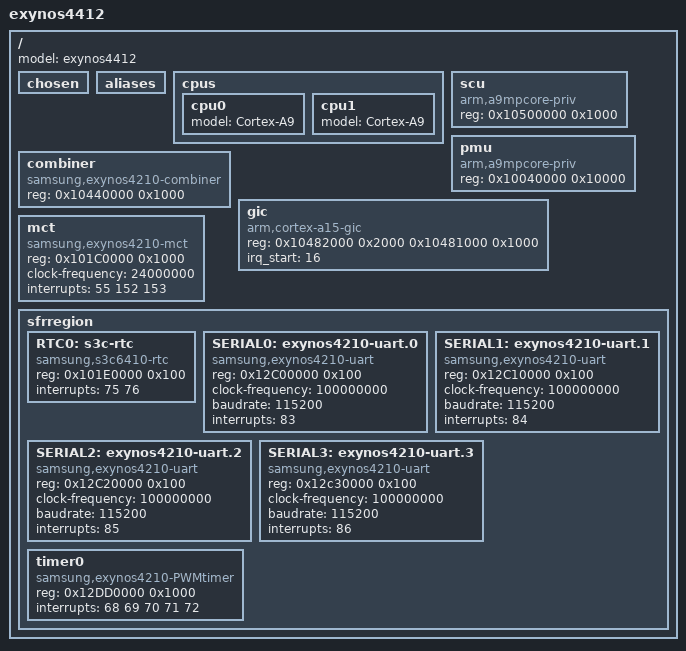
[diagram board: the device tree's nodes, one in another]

/ {
	#address-cells = <1>;
	#size-cells = <1>;
	model = "exynos4412";

	chosen { };
	aliases { };

	cpus {
		cpu0 {
			device_type = "cpu";
			model = "Cortex-A9";
		};

		cpu1 {
			device_type = "cpu";
			model = "Cortex-A9";
		};

	};

	scu { /* Snoop Control Unit */
		device_type = "scu";
		compatible = "arm,a9mpcore-priv";
		reg = <0x10500000 0x1000>;
	};

	pmu { /* Performance Monitorig Unit */
		device_type = "pmu";
		compatible = "arm,a9mpcore-priv";
		reg = <0x10040000 0x10000>;
	};

	combiner {
		compatible = "samsung,exynos4210-combiner";
		reg = <0x10440000 0x1000>;
	};

	gic {
		device_type = "pic";
		compatible = "arm,cortex-a15-gic";
		reg = <0x10482000 0x2000 0x10481000 0x1000>;
		irq_start = <16>;
	};

	mct {
		device_type = "timer";
		compatible = "samsung,exynos4210-mct";
		reg = <0x101C0000 0x1000>;
		clock-frequency = <24000000>;
		interrupts = <55 152 153>;
	};

	sfrregion {
		#address-cells = <1>;
		#size-cells = <1>;

		RTC0: s3c-rtc {
			device_type = "rtc";
			compatible = "samsung,s3c6410-rtc";
			reg = <0x101E0000 0x100>;
			interrupts = <75 76>;
		};

		SERIAL0: exynos4210-uart.0 {
			device_type = "serial";
			compatible = "samsung,exynos4210-uart";
			reg = <0x12C00000 0x100>;
			clock-frequency = <100000000>;
			baudrate = <115200>;
			interrupts = <83>;
		};

		SERIAL1: exynos4210-uart.1 {
			device_type = "serial";
			compatible = "samsung,exynos4210-uart";
			reg = <0x12C10000 0x100>;
			clock-frequency = <100000000>;
			baudrate = <115200>;
			interrupts = <84>;
		};

		SERIAL2: exynos4210-uart.2 {
			device_type = "serial";
			compatible = "samsung,exynos4210-uart";
			reg = <0x12C20000 0x100>;
			clock-frequency = <100000000>;
			baudrate = <115200>;
			interrupts = <85>;
		};

		SERIAL3: exynos4210-uart.3 {
			device_type = "serial";
			compatible = "samsung,exynos4210-uart";
			reg = <0x12c30000 0x100>;
			clock-frequency = <100000000>;
			baudrate = <115200>;
			interrupts = <86>;
		};

		timer0 {
			device_type = "timer";
			compatible = "samsung,exynos4210-PWMtimer";
			reg = <0x12DD0000 0x1000>;
			interrupts = <68 69 70 71 72>;
		};
	};
};
